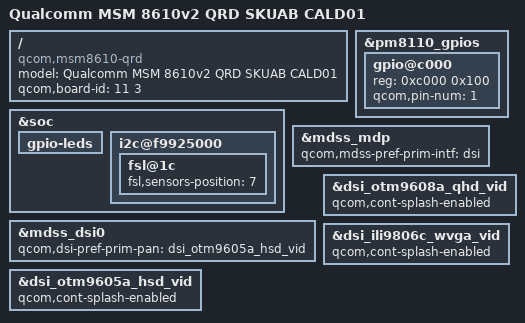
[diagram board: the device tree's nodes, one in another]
/* Copyright (c) 2013, The Linux Foundation. All rights reserved.
 *
 * This program is free software; you can redistribute it and/or modify
 * it under the terms of the GNU General Public License version 2 and
 * only version 2 as published by the Free Software Foundation.
 *
 * This program is distributed in the hope that it will be useful,
 * but WITHOUT ANY WARRANTY; without even the implied warranty of
 * MERCHANTABILITY or FITNESS FOR A PARTICULAR PURPOSE.  See the
 * GNU General Public License for more details.
 */

/dts-v1/;

/include/ "msm8610-v2.dtsi"
/include/ "msm8610-qrd-skuab.dtsi"
/include/ "msm8610-goso-cald01-camera-sensor.dtsi"

/ {
	model = "Qualcomm MSM 8610v2 QRD SKUAB CALD01";
	compatible = "qcom,msm8610-qrd", "qcom,msm8610", "qcom,qrd";
	qcom,board-id = <11 3>;
};

&soc {
	gpio-leds {
		status = "ok";
	};
};

&pm8110_gpios {
	gpio@c000 { /* GPIO 1 */
		reg = <0xc000 0x100>;
		qcom,pin-num = <1>;
	};
};

&mdss_mdp {
	qcom,mdss-pref-prim-intf = "dsi";
};

&mdss_dsi0 {
	qcom,dsi-pref-prim-pan = <&dsi_otm9608a_qhd_vid>;
};

&dsi_otm9608a_qhd_vid {
	qcom,cont-splash-enabled;
};

&mdss_dsi0 {
qcom,dsi-pref-prim-pan = <&dsi_ili9806c_wvga_vid>;
};
&dsi_ili9806c_wvga_vid {
qcom,cont-splash-enabled;
};

&mdss_dsi0 {
	qcom,dsi-pref-prim-pan = <&dsi_otm9605a_hsd_vid>;
};

&dsi_otm9605a_hsd_vid {
	qcom,cont-splash-enabled;
};

&soc {
	i2c@f9925000 {
		fsl@1c {
			fsl,sensors-position = <7>;
		};
	};
};
